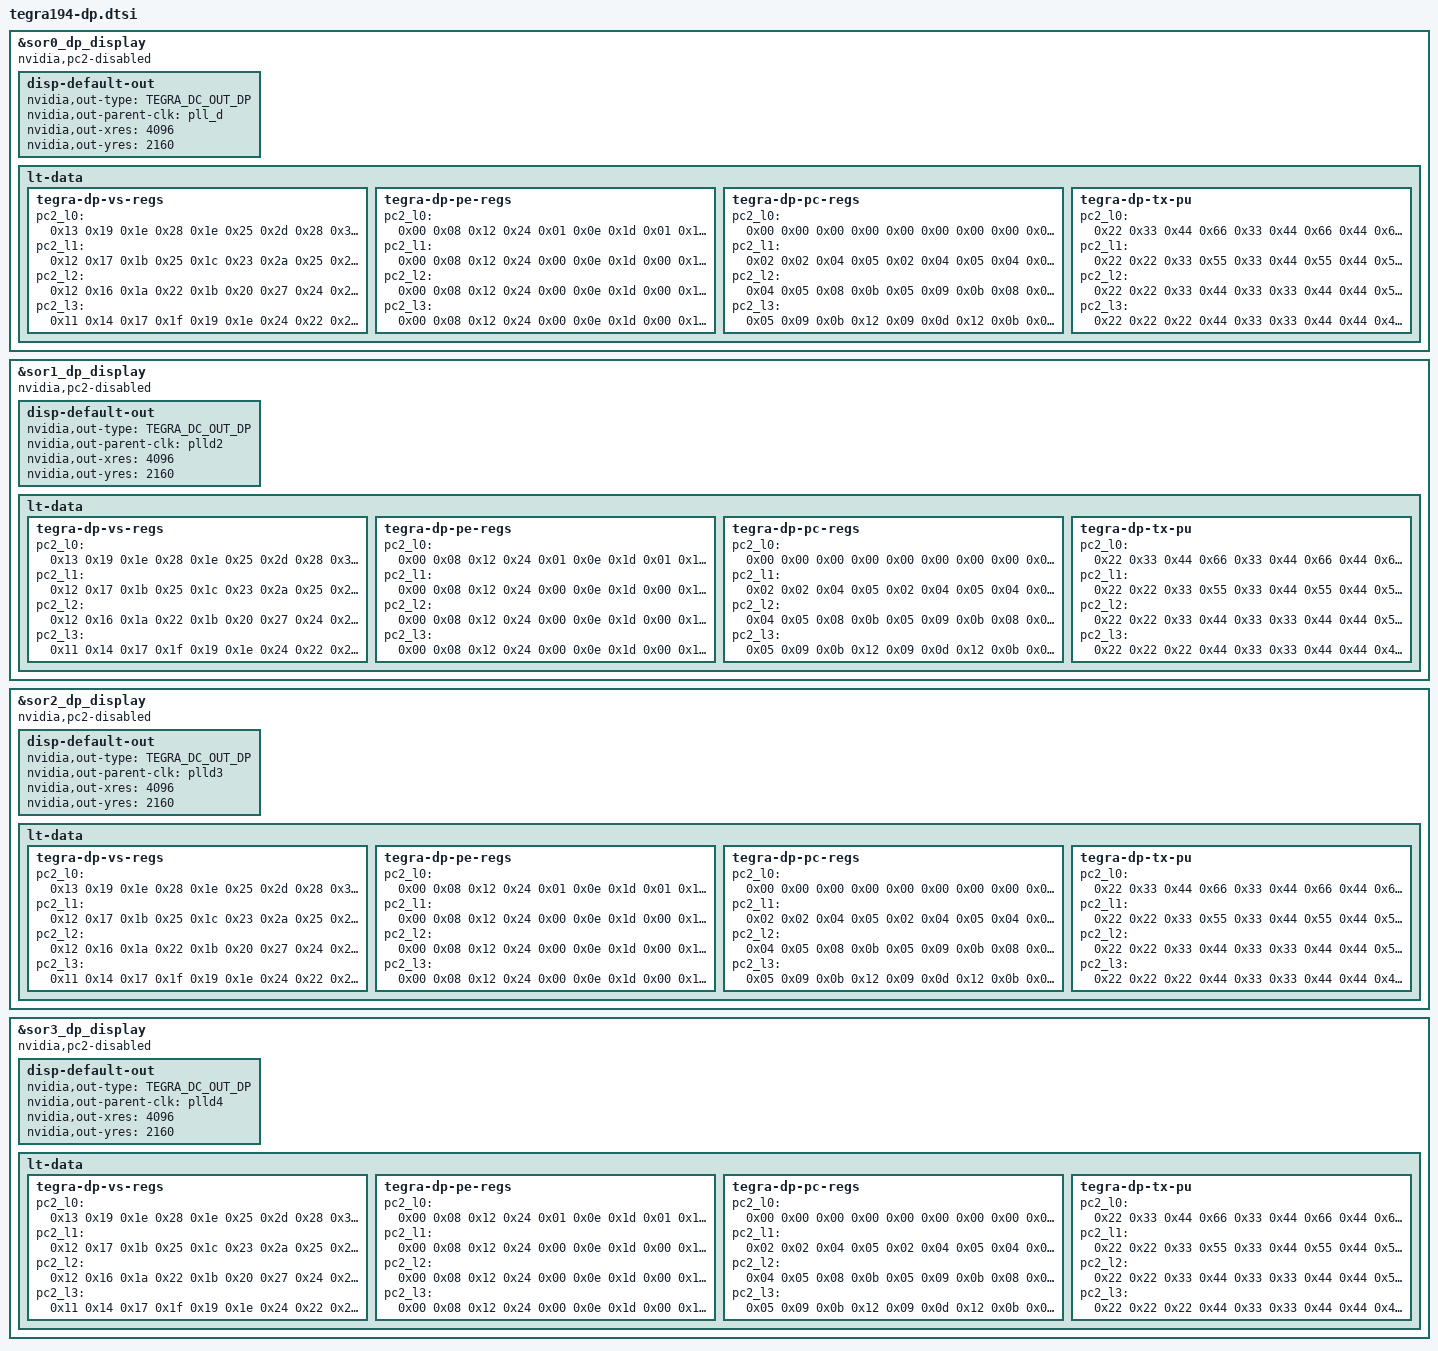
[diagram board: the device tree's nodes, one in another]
/*
 * tegra194-dp.dtsi:
 *
 * Copyright (c) 2017, NVIDIA CORPORATION.  All rights reserved.
 *
 * This program is free software; you can redistribute it and/or modify
 * it under the terms of the GNU General Public License as published by
 * the Free Software Foundation; version 2 of the License.
 *
 * This program is distributed in the hope that it will be useful, but WITHOUT
 * ANY WARRANTY; without even the implied warranty of MERCHANTABILITY or
 * FITNESS FOR A PARTICULAR PURPOSE.  See the GNU General Public License for
 * more details.
 */

#include <dt-bindings/display/tegra-dc.h>

&sor0_dp_display {
	nvidia,pc2-disabled;
	disp-default-out {
		nvidia,out-type = <TEGRA_DC_OUT_DP>;
		nvidia,out-parent-clk = "pll_d";
		nvidia,out-xres = <4096>;
		nvidia,out-yres = <2160>;
	};
	/* Setting for LT data */
	lt-data {
		tegra-dp-vs-regs {
			/* postcursor2 L0 */
			pc2_l0 = <
				/* pre-emphasis: L0, L1, L2, L3 */
				0x13 0x19 0x1e 0x28 /* voltage swing: L0 */
				0x1e 0x25 0x2d /* L1 */
				0x28 0x32 /* L2 */
				0x39 /* L3 */
			>;
			/* postcursor2 L1 */
			pc2_l1 = <
				0x12 0x17 0x1b 0x25
				0x1c 0x23 0x2a
				0x25 0x2f
				0x37
			>;
			/* postcursor2 L2 */
			pc2_l2 = <
				0x12 0x16 0x1a 0x22
				0x1b 0x20 0x27
				0x24 0x2d
				0x35
			>;
			/* postcursor2 L3 */
			pc2_l3 = <
				0x11 0x14 0x17 0x1f
				0x19 0x1e 0x24
				0x22 0x2a
				0x32
			>;
		};
		tegra-dp-pe-regs {
			/* postcursor2 L0 */
			pc2_l0 = <
				/* pre-emphasis: L0, L1, L2, L3 */
				0x00 0x08 0x12 0x24 /* voltage swing: L0 */
				0x01 0x0e 0x1d /* L1 */
				0x01 0x13 /* L2 */
				0x00 /* L3 */
			>;
			/* postcursor2 L1 */
			pc2_l1 = <
				0x00 0x08 0x12 0x24
				0x00 0x0e 0x1d
				0x00 0x13
				0x00
			>;
			/* postcursor2 L2 */
			pc2_l2 = <
				0x00 0x08 0x12 0x24
				0x00 0x0e 0x1d
				0x00 0x13
				0x00
			>;
			/* postcursor2 L3 */
			pc2_l3 = <
				0x00 0x08 0x12 0x24
				0x00 0x0e 0x1d
				0x00 0x13
				0x00
			>;
		};
		tegra-dp-pc-regs {
			/* postcursor2 L0 */
			pc2_l0 = <
				/* pre-emphasis: L0, L1, L2, L3 */
				0x00 0x00 0x00 0x00 /* voltage swing: L0 */
				0x00 0x00 0x00 /* L1 */
				0x00 0x00 /* L2 */
				0x00 /* L3 */
			>;
			/* postcursor2 L1 */
			pc2_l1 = <
				0x02 0x02 0x04 0x05
				0x02 0x04 0x05
				0x04 0x05
				0x05
			>;
			/* postcursor2 L2 */
			pc2_l2 = <
				0x04 0x05 0x08 0x0b
				0x05 0x09 0x0b
				0x08 0x0a
				0x0b
			>;
			/* postcursor2 L3 */
			pc2_l3 = <
				0x05 0x09 0x0b 0x12
				0x09 0x0d 0x12
				0x0b 0x0f
				0x12
			>;
		};
		tegra-dp-tx-pu {
			/* postcursor2 L0 */
			pc2_l0 = <
				/* pre-emphasis: L0, L1, L2, L3 */
				0x22 0x33 0x44 0x66 /* voltage swing: L0 */
				0x33 0x44 0x66 /* L1 */
				0x44 0x66 /* L2 */
				0x66 /* L3 */
			>;
			/* postcursor2 L1 */
			pc2_l1 = <
				0x22 0x22 0x33 0x55
				0x33 0x44 0x55
				0x44 0x55
				0x66
			>;
			/* postcursor2 L2 */
			pc2_l2 = <
				0x22 0x22 0x33 0x44
				0x33 0x33 0x44
				0x44 0x55
				0x66
			>;
			/* postcursor2 L3 */
			pc2_l3 = <
				0x22 0x22 0x22 0x44
				0x33 0x33 0x44
				0x44 0x44
				0x66
			>;
		};
	};//lt-data;
};

&sor1_dp_display {
	nvidia,pc2-disabled;
	disp-default-out {
		nvidia,out-type = <TEGRA_DC_OUT_DP>;
		nvidia,out-parent-clk = "plld2";
		nvidia,out-xres = <4096>;
		nvidia,out-yres = <2160>;
	};
	/* Setting for LT data */
	lt-data {
		tegra-dp-vs-regs {
			/* postcursor2 L0 */
			pc2_l0 = <
				/* pre-emphasis: L0, L1, L2, L3 */
				0x13 0x19 0x1e 0x28 /* voltage swing: L0 */
				0x1e 0x25 0x2d /* L1 */
				0x28 0x32 /* L2 */
				0x39 /* L3 */
			>;
			/* postcursor2 L1 */
			pc2_l1 = <
				0x12 0x17 0x1b 0x25
				0x1c 0x23 0x2a
				0x25 0x2f
				0x37
			>;
			/* postcursor2 L2 */
			pc2_l2 = <
				0x12 0x16 0x1a 0x22
				0x1b 0x20 0x27
				0x24 0x2d
				0x35
			>;
			/* postcursor2 L3 */
			pc2_l3 = <
				0x11 0x14 0x17 0x1f
				0x19 0x1e 0x24
				0x22 0x2a
				0x32
			>;
		};
		tegra-dp-pe-regs {
			/* postcursor2 L0 */
			pc2_l0 = <
				/* pre-emphasis: L0, L1, L2, L3 */
				0x00 0x08 0x12 0x24 /* voltage swing: L0 */
				0x01 0x0e 0x1d /* L1 */
				0x01 0x13 /* L2 */
				0x00 /* L3 */
			>;
			/* postcursor2 L1 */
			pc2_l1 = <
				0x00 0x08 0x12 0x24
				0x00 0x0e 0x1d
				0x00 0x13
				0x00
			>;
			/* postcursor2 L2 */
			pc2_l2 = <
				0x00 0x08 0x12 0x24
				0x00 0x0e 0x1d
				0x00 0x13
				0x00
			>;
			/* postcursor2 L3 */
			pc2_l3 = <
				0x00 0x08 0x12 0x24
				0x00 0x0e 0x1d
				0x00 0x13
				0x00
			>;
		};
		tegra-dp-pc-regs {
			/* postcursor2 L0 */
			pc2_l0 = <
				/* pre-emphasis: L0, L1, L2, L3 */
				0x00 0x00 0x00 0x00 /* voltage swing: L0 */
				0x00 0x00 0x00 /* L1 */
				0x00 0x00 /* L2 */
				0x00 /* L3 */
			>;
			/* postcursor2 L1 */
			pc2_l1 = <
				0x02 0x02 0x04 0x05
				0x02 0x04 0x05
				0x04 0x05
				0x05
			>;
			/* postcursor2 L2 */
			pc2_l2 = <
				0x04 0x05 0x08 0x0b
				0x05 0x09 0x0b
				0x08 0x0a
				0x0b
			>;
			/* postcursor2 L3 */
			pc2_l3 = <
				0x05 0x09 0x0b 0x12
				0x09 0x0d 0x12
				0x0b 0x0f
				0x12
			>;
		};
		tegra-dp-tx-pu {
			/* postcursor2 L0 */
			pc2_l0 = <
				/* pre-emphasis: L0, L1, L2, L3 */
				0x22 0x33 0x44 0x66 /* voltage swing: L0 */
				0x33 0x44 0x66 /* L1 */
				0x44 0x66 /* L2 */
				0x66 /* L3 */
			>;
			/* postcursor2 L1 */
			pc2_l1 = <
				0x22 0x22 0x33 0x55
				0x33 0x44 0x55
				0x44 0x55
				0x66
			>;
			/* postcursor2 L2 */
			pc2_l2 = <
				0x22 0x22 0x33 0x44
				0x33 0x33 0x44
				0x44 0x55
				0x66
			>;
			/* postcursor2 L3 */
			pc2_l3 = <
				0x22 0x22 0x22 0x44
				0x33 0x33 0x44
				0x44 0x44
				0x66
			>;
		};
	};//lt-data;
};

&sor2_dp_display {
	nvidia,pc2-disabled;
	disp-default-out {
		nvidia,out-type = <TEGRA_DC_OUT_DP>;
		nvidia,out-parent-clk = "plld3";
		nvidia,out-xres = <4096>;
		nvidia,out-yres = <2160>;
	};
	/* Setting for LT data */
	lt-data {
		tegra-dp-vs-regs {
			/* postcursor2 L0 */
			pc2_l0 = <
				/* pre-emphasis: L0, L1, L2, L3 */
				0x13 0x19 0x1e 0x28 /* voltage swing: L0 */
				0x1e 0x25 0x2d /* L1 */
				0x28 0x32 /* L2 */
				0x39 /* L3 */
			>;
			/* postcursor2 L1 */
			pc2_l1 = <
				0x12 0x17 0x1b 0x25
				0x1c 0x23 0x2a
				0x25 0x2f
				0x37
			>;
			/* postcursor2 L2 */
			pc2_l2 = <
				0x12 0x16 0x1a 0x22
				0x1b 0x20 0x27
				0x24 0x2d
				0x35
			>;
			/* postcursor2 L3 */
			pc2_l3 = <
				0x11 0x14 0x17 0x1f
				0x19 0x1e 0x24
				0x22 0x2a
				0x32
			>;
		};
		tegra-dp-pe-regs {
			/* postcursor2 L0 */
			pc2_l0 = <
				/* pre-emphasis: L0, L1, L2, L3 */
				0x00 0x08 0x12 0x24 /* voltage swing: L0 */
				0x01 0x0e 0x1d /* L1 */
				0x01 0x13 /* L2 */
				0x00 /* L3 */
			>;
			/* postcursor2 L1 */
			pc2_l1 = <
				0x00 0x08 0x12 0x24
				0x00 0x0e 0x1d
				0x00 0x13
				0x00
			>;
			/* postcursor2 L2 */
			pc2_l2 = <
				0x00 0x08 0x12 0x24
				0x00 0x0e 0x1d
				0x00 0x13
				0x00
			>;
			/* postcursor2 L3 */
			pc2_l3 = <
				0x00 0x08 0x12 0x24
				0x00 0x0e 0x1d
				0x00 0x13
				0x00
			>;
		};
		tegra-dp-pc-regs {
			/* postcursor2 L0 */
			pc2_l0 = <
				/* pre-emphasis: L0, L1, L2, L3 */
				0x00 0x00 0x00 0x00 /* voltage swing: L0 */
				0x00 0x00 0x00 /* L1 */
				0x00 0x00 /* L2 */
				0x00 /* L3 */
			>;
			/* postcursor2 L1 */
			pc2_l1 = <
				0x02 0x02 0x04 0x05
				0x02 0x04 0x05
				0x04 0x05
				0x05
			>;
			/* postcursor2 L2 */
			pc2_l2 = <
				0x04 0x05 0x08 0x0b
				0x05 0x09 0x0b
				0x08 0x0a
				0x0b
			>;
			/* postcursor2 L3 */
			pc2_l3 = <
				0x05 0x09 0x0b 0x12
				0x09 0x0d 0x12
				0x0b 0x0f
				0x12
			>;
		};
		tegra-dp-tx-pu {
			/* postcursor2 L0 */
			pc2_l0 = <
				/* pre-emphasis: L0, L1, L2, L3 */
				0x22 0x33 0x44 0x66 /* voltage swing: L0 */
				0x33 0x44 0x66 /* L1 */
				0x44 0x66 /* L2 */
				0x66 /* L3 */
			>;
			/* postcursor2 L1 */
			pc2_l1 = <
				0x22 0x22 0x33 0x55
				0x33 0x44 0x55
				0x44 0x55
				0x66
			>;
			/* postcursor2 L2 */
			pc2_l2 = <
				0x22 0x22 0x33 0x44
				0x33 0x33 0x44
				0x44 0x55
				0x66
			>;
			/* postcursor2 L3 */
			pc2_l3 = <
				0x22 0x22 0x22 0x44
				0x33 0x33 0x44
				0x44 0x44
				0x66
			>;
		};
	};//lt-data;
};

&sor3_dp_display {
	nvidia,pc2-disabled;
	disp-default-out {
		nvidia,out-type = <TEGRA_DC_OUT_DP>;
		nvidia,out-parent-clk = "plld4";
		nvidia,out-xres = <4096>;
		nvidia,out-yres = <2160>;
	};
	/* Setting for LT data */
	lt-data {
		tegra-dp-vs-regs {
			/* postcursor2 L0 */
			pc2_l0 = <
				/* pre-emphasis: L0, L1, L2, L3 */
				0x13 0x19 0x1e 0x28 /* voltage swing: L0 */
				0x1e 0x25 0x2d /* L1 */
				0x28 0x32 /* L2 */
				0x39 /* L3 */
			>;
			/* postcursor2 L1 */
			pc2_l1 = <
				0x12 0x17 0x1b 0x25
				0x1c 0x23 0x2a
				0x25 0x2f
				0x37
			>;
			/* postcursor2 L2 */
			pc2_l2 = <
				0x12 0x16 0x1a 0x22
				0x1b 0x20 0x27
				0x24 0x2d
				0x35
			>;
			/* postcursor2 L3 */
			pc2_l3 = <
				0x11 0x14 0x17 0x1f
				0x19 0x1e 0x24
				0x22 0x2a
				0x32
			>;
		};
		tegra-dp-pe-regs {
			/* postcursor2 L0 */
			pc2_l0 = <
				/* pre-emphasis: L0, L1, L2, L3 */
				0x00 0x08 0x12 0x24 /* voltage swing: L0 */
				0x01 0x0e 0x1d /* L1 */
				0x01 0x13 /* L2 */
				0x00 /* L3 */
			>;
			/* postcursor2 L1 */
			pc2_l1 = <
				0x00 0x08 0x12 0x24
				0x00 0x0e 0x1d
				0x00 0x13
				0x00
			>;
			/* postcursor2 L2 */
			pc2_l2 = <
				0x00 0x08 0x12 0x24
				0x00 0x0e 0x1d
				0x00 0x13
				0x00
			>;
			/* postcursor2 L3 */
			pc2_l3 = <
				0x00 0x08 0x12 0x24
				0x00 0x0e 0x1d
				0x00 0x13
				0x00
			>;
		};
		tegra-dp-pc-regs {
			/* postcursor2 L0 */
			pc2_l0 = <
				/* pre-emphasis: L0, L1, L2, L3 */
				0x00 0x00 0x00 0x00 /* voltage swing: L0 */
				0x00 0x00 0x00 /* L1 */
				0x00 0x00 /* L2 */
				0x00 /* L3 */
			>;
			/* postcursor2 L1 */
			pc2_l1 = <
				0x02 0x02 0x04 0x05
				0x02 0x04 0x05
				0x04 0x05
				0x05
			>;
			/* postcursor2 L2 */
			pc2_l2 = <
				0x04 0x05 0x08 0x0b
				0x05 0x09 0x0b
				0x08 0x0a
				0x0b
			>;
			/* postcursor2 L3 */
			pc2_l3 = <
				0x05 0x09 0x0b 0x12
				0x09 0x0d 0x12
				0x0b 0x0f
				0x12
			>;
		};
		tegra-dp-tx-pu {
			/* postcursor2 L0 */
			pc2_l0 = <
				/* pre-emphasis: L0, L1, L2, L3 */
				0x22 0x33 0x44 0x66 /* voltage swing: L0 */
				0x33 0x44 0x66 /* L1 */
				0x44 0x66 /* L2 */
				0x66 /* L3 */
			>;
			/* postcursor2 L1 */
			pc2_l1 = <
				0x22 0x22 0x33 0x55
				0x33 0x44 0x55
				0x44 0x55
				0x66
			>;
			/* postcursor2 L2 */
			pc2_l2 = <
				0x22 0x22 0x33 0x44
				0x33 0x33 0x44
				0x44 0x55
				0x66
			>;
			/* postcursor2 L3 */
			pc2_l3 = <
				0x22 0x22 0x22 0x44
				0x33 0x33 0x44
				0x44 0x44
				0x66
			>;
		};
	};//lt-data;
};
